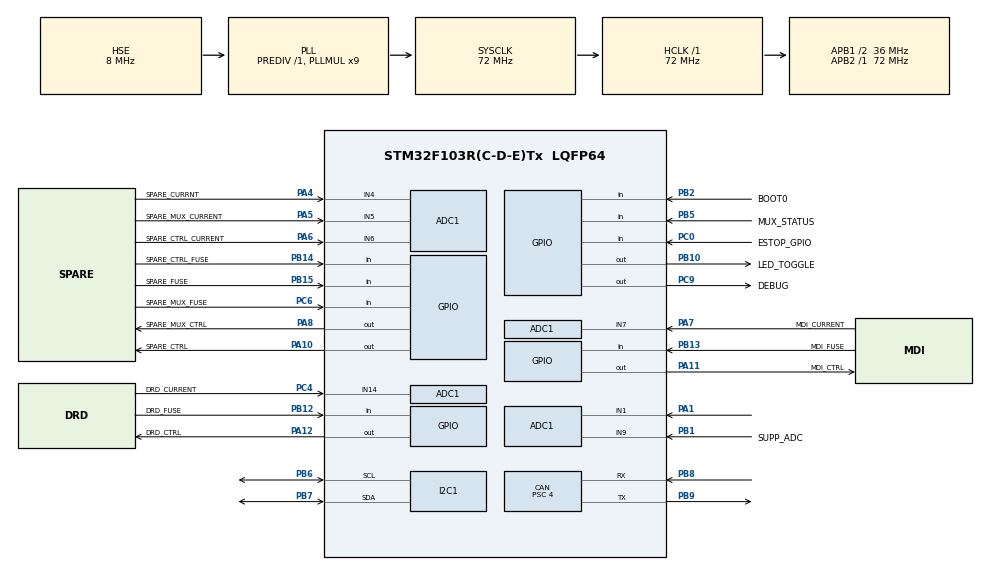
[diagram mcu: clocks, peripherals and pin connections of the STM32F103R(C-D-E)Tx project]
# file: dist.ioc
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ADC1.Channel-0\#ChannelRegularConversion=ADC_CHANNEL_1
ADC1.NbrOfConversionFlag=1
ADC1.Rank-0\#ChannelRegularConversion=1
ADC1.SamplingTime-0\#ChannelRegularConversion=ADC_SAMPLETIME_1CYCLE_5
ADC1.master=1
CAN.BS1=CAN_BS1_15TQ
CAN.BS2=CAN_BS2_2TQ
CAN.CalculateBaudRate=500000
CAN.CalculateTimeBit=2000
CAN.CalculateTimeQuantum=111.11111111111111
CAN.Prescaler=4
Mcu.Family=STM32F1
Mcu.Name=STM32F103R(C-D-E)Tx
Mcu.Package=LQFP64
NVIC.CAN1_RX1_IRQn=true\:0\:0\:false\:false\:true\:true\:true\:true
NVIC.PriorityGroup=NVIC_PRIORITYGROUP_4
NVIC.USB_HP_CAN1_TX_IRQn=true\:0\:0\:false\:false\:true\:true\:true\:true
NVIC.USB_LP_CAN1_RX0_IRQn=true\:0\:0\:false\:false\:true\:true\:true\:true
PA1.Signal=ADCx_IN1
PA10.GPIO_Label=SPARE_CTRL
PA10.Signal=GPIO_Output
PA11.GPIO_Label=MDI_CTRL
PA11.Signal=GPIO_Output
PA12.GPIO_Label=DRD_CTRL
PA12.Signal=GPIO_Output
PA13.Mode=Trace_Asynchronous_SW
PA13.Signal=SYS_JTMS-SWDIO
PA14.Mode=Trace_Asynchronous_SW
PA14.Signal=SYS_JTCK-SWCLK
PA4.GPIO_Label=SPARE_CURRNT
PA4.Signal=ADCx_IN4
PA5.GPIO_Label=SPARE_MUX_CURRENT
PA5.Signal=ADCx_IN5
PA6.GPIO_Label=SPARE_CTRL_CURRENT
PA6.Signal=ADCx_IN6
PA7.GPIO_Label=MDI_CURRENT
PA7.Signal=ADCx_IN7
PA8.GPIO_Label=SPARE_MUX_CTRL
PA8.Signal=GPIO_Output
PB1.GPIO_Label=SUPP_ADC
PB1.Signal=ADCx_IN9
PB10.GPIO_Label=LED_TOGGLE
PB10.Signal=GPIO_Output
PB12.GPIO_Label=DRD_FUSE
PB12.Signal=GPIO_Input
PB13.GPIO_Label=MDI_FUSE
PB13.Signal=GPIO_Input
PB14.GPIO_Label=SPARE_CTRL_FUSE
PB14.Signal=GPIO_Input
PB15.GPIO_Label=SPARE_FUSE
PB15.Signal=GPIO_Input
PB2.GPIO_Label=BOOT0
PB2.Signal=GPIO_Input
PB3.Mode=Trace_Asynchronous_SW
PB3.Signal=SYS_JTDO-TRACESWO
PB5.GPIO_Label=MUX_STATUS
PB5.Signal=GPIO_Input
PB6.Mode=I2C
PB6.Signal=I2C1_SCL
PB7.Mode=I2C
PB7.Signal=I2C1_SDA
PB8.Mode=CAN_Activate
PB8.Signal=CAN_RX
PB9.Mode=CAN_Activate
PB9.Signal=CAN_TX
PC0.GPIO_Label=ESTOP_GPIO
PC0.Signal=GPIO_Input
PC4.GPIO_Label=DRD_CURRENT
PC4.Signal=ADCx_IN14
PC6.GPIO_Label=SPARE_MUX_FUSE
PC6.Signal=GPIO_Input
PC9.GPIO_Label=DEBUG
PC9.Signal=GPIO_Output
PD0-OSC_IN.Mode=HSE-External-Oscillator
PD0-OSC_IN.Signal=RCC_OSC_IN
PD1-OSC_OUT.Mode=HSE-External-Oscillator
PD1-OSC_OUT.Signal=RCC_OSC_OUT
ProjectManager.HeapSize=0x200
ProjectManager.StackSize=0x400
ProjectManager.TargetToolchain=CMake
RCC.ADCPresc=RCC_ADCPCLK2_DIV6
RCC.AHBFreq_Value=72000000
RCC.APB1CLKDivider=RCC_HCLK_DIV2
RCC.APB1Freq_Value=36000000
RCC.APB1TimFreq_Value=72000000
RCC.APB2Freq_Value=72000000
RCC.APB2TimFreq_Value=72000000
RCC.FLatency=FLASH_LATENCY_2
RCC.HCLKFreq_Value=72000000
RCC.PLLMUL=RCC_PLL_MUL9
RCC.PLLSourceVirtual=RCC_PLLSOURCE_HSE
RCC.SYSCLKFreq_VALUE=72000000
RCC.SYSCLKSource=RCC_SYSCLKSOURCE_PLLCLK
RCC.USBFreq_Value=72000000
SH.ADCx_IN1.0=ADC1_IN1,IN1
SH.ADCx_IN14.0=ADC1_IN14,IN14
SH.ADCx_IN4.0=ADC1_IN4,IN4
SH.ADCx_IN5.0=ADC1_IN5,IN5
SH.ADCx_IN6.0=ADC1_IN6,IN6
SH.ADCx_IN7.0=ADC1_IN7,IN7
SH.ADCx_IN9.0=ADC1_IN9,IN9
board=custom

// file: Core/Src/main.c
/* USER CODE BEGIN Header */
/**
  ******************************************************************************
  * @file           : main.c
  * @brief          : Main program body
  ******************************************************************************
  * @attention
  *
  * Copyright (c) 2026 STMicroelectronics.
  * All rights reserved.
  *
  * This software is licensed under terms that can be found in the LICENSE file
  * in the root directory of this software component.
  * If no LICENSE file comes with this software, it is provided AS-IS.
  *
  ******************************************************************************
  */
/* USER CODE END Header */
#include "main.h"
#include "adc.h"
#include "can.h"
#include "i2c.h"
#include "gpio.h"

/* USER CODE BEGIN Includes */
#include "dist_main.h"

/* USER CODE END Includes */

void SystemClock_Config(void);

int main(void)
{

  /* MCU Configuration--------------------------------------------------------*/

  /* Reset of all peripherals, Initializes the Flash interface and the Systick. */
  HAL_Init();

  /* Configure the system clock */
  SystemClock_Config();

  /* Initialize all configured peripherals */
  MX_GPIO_Init();
  MX_ADC1_Init();
  MX_I2C1_Init();
  MX_CAN_Init();
  /* USER CODE BEGIN 2 */
  AppMain();
  /* USER CODE END 2 */

  /* Infinite loop */
  while (1)
  {

  }
}

void SystemClock_Config(void)
{
  RCC_OscInitTypeDef RCC_OscInitStruct = {0};
  RCC_ClkInitTypeDef RCC_ClkInitStruct = {0};
  RCC_PeriphCLKInitTypeDef PeriphClkInit = {0};

  /** Initializes the RCC Oscillators according to the specified parameters
  * in the RCC_OscInitTypeDef structure.
  */
  RCC_OscInitStruct.OscillatorType = RCC_OSCILLATORTYPE_HSE;
  RCC_OscInitStruct.HSEState = RCC_HSE_ON;
  RCC_OscInitStruct.HSEPredivValue = RCC_HSE_PREDIV_DIV1;
  RCC_OscInitStruct.HSIState = RCC_HSI_ON;
  RCC_OscInitStruct.PLL.PLLState = RCC_PLL_ON;
  RCC_OscInitStruct.PLL.PLLSource = RCC_PLLSOURCE_HSE;
  RCC_OscInitStruct.PLL.PLLMUL = RCC_PLL_MUL9;
  if (HAL_RCC_OscConfig(&RCC_OscInitStruct) != HAL_OK)
  {
    Error_Handler();
  }

  /** Initializes the CPU, AHB and APB buses clocks
  */
  RCC_ClkInitStruct.ClockType = RCC_CLOCKTYPE_HCLK|RCC_CLOCKTYPE_SYSCLK
                              |RCC_CLOCKTYPE_PCLK1|RCC_CLOCKTYPE_PCLK2;
  RCC_ClkInitStruct.SYSCLKSource = RCC_SYSCLKSOURCE_PLLCLK;
  RCC_ClkInitStruct.AHBCLKDivider = RCC_SYSCLK_DIV1;
  RCC_ClkInitStruct.APB1CLKDivider = RCC_HCLK_DIV2;
  RCC_ClkInitStruct.APB2CLKDivider = RCC_HCLK_DIV1;

  if (HAL_RCC_ClockConfig(&RCC_ClkInitStruct, FLASH_LATENCY_2) != HAL_OK)
  {
    Error_Handler();
  }
  PeriphClkInit.PeriphClockSelection = RCC_PERIPHCLK_ADC;
  PeriphClkInit.AdcClockSelection = RCC_ADCPCLK2_DIV6;
  if (HAL_RCCEx_PeriphCLKConfig(&PeriphClkInit) != HAL_OK)
  {
    Error_Handler();
  }
}

void Error_Handler(void)
{
  __disable_irq();
  while (1)
  {
  }
}
